VERSION ""

NS_ :

BS_: 500000

BU_: AEB_Controller Vehicle_ECU Radar_ECU

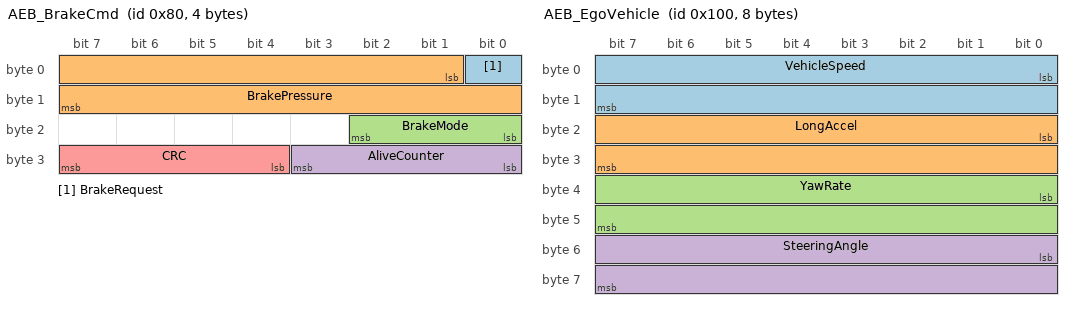
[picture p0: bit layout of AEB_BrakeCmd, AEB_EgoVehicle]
BO_ 128 AEB_BrakeCmd: 4 AEB_Controller
 SG_ BrakeRequest : 0|1@1+ (1,0) [0|1] "" Vehicle_ECU
 SG_ BrakePressure : 1|15@1+ (0.1,0) [0|3276.7] "bar" Vehicle_ECU
 SG_ BrakeMode : 16|3@1+ (1,0) [0|7] "" Vehicle_ECU
 SG_ AliveCounter : 24|4@1+ (1,0) [0|15] "" Vehicle_ECU
 SG_ CRC : 28|4@1+ (1,0) [0|15] "" Vehicle_ECU

BO_ 256 AEB_EgoVehicle: 8 Vehicle_ECU
 SG_ VehicleSpeed : 0|16@1+ (0.01,0) [0|655.35] "m/s" AEB_Controller
 SG_ LongAccel : 16|16@1+ (0.001,-32) [-32|33.535] "m/s^2" AEB_Controller
 SG_ YawRate : 32|16@1+ (0.01,-327.68) [-327.68|327.67] "deg/s" AEB_Controller
 SG_ SteeringAngle : 48|16@1+ (0.1,-3276.8) [-3276.8|3276.7] "deg" AEB_Controller

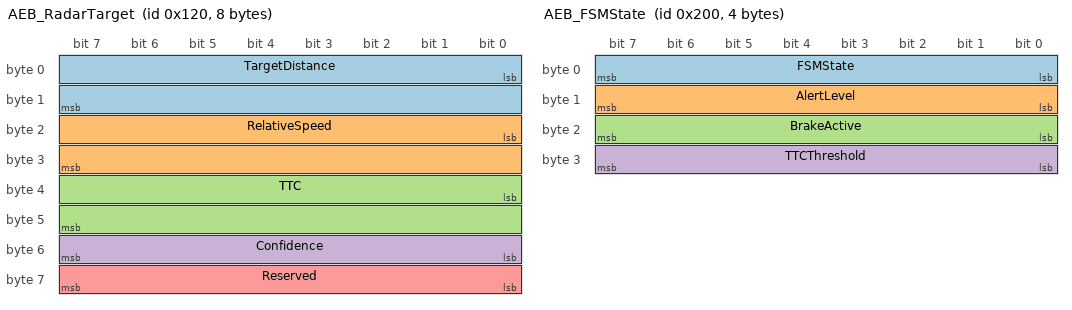
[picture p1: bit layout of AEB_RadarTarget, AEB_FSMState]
BO_ 288 AEB_RadarTarget: 8 Radar_ECU
 SG_ TargetDistance : 0|16@1+ (0.01,0) [0|655.35] "m" AEB_Controller
 SG_ RelativeSpeed : 16|16@1+ (0.01,-327.68) [-327.68|327.67] "m/s" AEB_Controller
 SG_ TTC : 32|16@1+ (0.001,0) [0|65.535] "s" AEB_Controller
 SG_ Confidence : 48|8@1+ (1,0) [0|15] "" AEB_Controller
 SG_ Reserved : 56|8@1+ (1,0) [0|255] "" AEB_Controller

BO_ 512 AEB_FSMState: 4 AEB_Controller
 SG_ FSMState : 0|8@1+ (1,0) [0|6] "" Vehicle_ECU,Radar_ECU
 SG_ AlertLevel : 8|8@1+ (1,0) [0|3] "" Vehicle_ECU,Radar_ECU
 SG_ BrakeActive : 16|8@1+ (1,0) [0|1] "" Vehicle_ECU,Radar_ECU
 SG_ TTCThreshold : 24|8@1+ (0.1,0) [0|25.5] "s" Vehicle_ECU,Radar_ECU

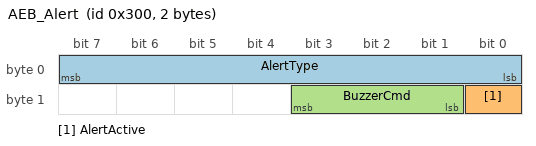
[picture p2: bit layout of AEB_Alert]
BO_ 768 AEB_Alert: 2 AEB_Controller
 SG_ AlertType : 0|8@1+ (1,0) [0|3] "" Vehicle_ECU
 SG_ AlertActive : 8|1@1+ (1,0) [0|1] "" Vehicle_ECU
 SG_ BuzzerCmd : 9|3@1+ (1,0) [0|7] "" Vehicle_ECU

CM_ BU_ AEB_Controller "AEB electronic control unit - FSM, TTC calculation, brake control";
CM_ BU_ Vehicle_ECU "Vehicle body ECU - speed, acceleration, yaw rate, steering";
CM_ BU_ Radar_ECU "77 GHz forward-looking radar sensor ECU";

CM_ BO_ 128 "Brake command from AEB controller to vehicle brake actuator. Period: 10 ms. Safety-critical ASIL B.";
CM_ BO_ 256 "Ego vehicle dynamics data from vehicle ECU. Period: 10 ms.";
CM_ BO_ 288 "Primary radar target data from radar ECU. Period: 20 ms.";
CM_ BO_ 512 "AEB finite state machine status. Period: 50 ms.";
CM_ BO_ 768 "Alert commands for HMI (visual/audible warnings). Event-driven.";

CM_ SG_ 128 BrakeRequest "Brake activation request: 0=no brake, 1=brake active";
CM_ SG_ 128 BrakePressure "Requested brake pressure in bar";
CM_ SG_ 128 BrakeMode "Brake mode: 0=off, 1=warning, 2=partial(L1), 3=moderate(L2), 4=full(L3), 5=post-brake hold";
CM_ SG_ 128 AliveCounter "4-bit rolling counter for message alive monitoring";
CM_ SG_ 128 CRC "4-bit CRC for message integrity check";
CM_ SG_ 256 VehicleSpeed "Ego vehicle longitudinal speed";
CM_ SG_ 256 LongAccel "Ego vehicle longitudinal acceleration (negative = braking)";
CM_ SG_ 256 YawRate "Ego vehicle yaw rate";
CM_ SG_ 256 SteeringAngle "Steering wheel angle (positive = left)";
CM_ SG_ 288 TargetDistance "Distance to primary radar target";
CM_ SG_ 288 RelativeSpeed "Relative speed to target (negative = closing)";
CM_ SG_ 288 TTC "Time-to-collision with primary target";
CM_ SG_ 288 Confidence "Target detection confidence level (0=no target, 15=highest)";
CM_ SG_ 512 FSMState "Current AEB finite state machine state";
CM_ SG_ 512 AlertLevel "Current alert/intervention level";
CM_ SG_ 512 BrakeActive "Brake system currently active flag";
CM_ SG_ 512 TTCThreshold "Current TTC threshold for active state";
CM_ SG_ 768 AlertType "Type of alert: visual, audible, or both";
CM_ SG_ 768 AlertActive "Alert currently active flag";
CM_ SG_ 768 BuzzerCmd "Buzzer pattern command";

BA_DEF_ BO_ "GenMsgCycleTime" INT 0 10000;

BA_ "GenMsgCycleTime" BO_ 128 10;
BA_ "GenMsgCycleTime" BO_ 256 10;
BA_ "GenMsgCycleTime" BO_ 288 20;
BA_ "GenMsgCycleTime" BO_ 512 50;
BA_ "GenMsgCycleTime" BO_ 768 0;

VAL_ 128 BrakeMode 0 "Off" 1 "Warning" 2 "Partial_L1" 3 "Moderate_L2" 4 "Full_L3" 5 "PostBrakeHold" ;
VAL_ 512 FSMState 0 "OFF" 1 "STANDBY" 2 "WARNING" 3 "BRAKE_L1" 4 "BRAKE_L2" 5 "BRAKE_L3" 6 "POST_BRAKE" ;
VAL_ 512 AlertLevel 0 "NONE" 1 "WARNING" 2 "BRAKE_LOW" 3 "BRAKE_HIGH" ;
VAL_ 768 AlertType 0 "NONE" 1 "VISUAL" 2 "AUDIBLE" 3 "BOTH" ;
VAL_ 768 BuzzerCmd 0 "Off" 1 "SingleBeep" 2 "DoubleBeep" 3 "ContinuousBeep" 4 "FastPulse" 5 "Chirp" ;
